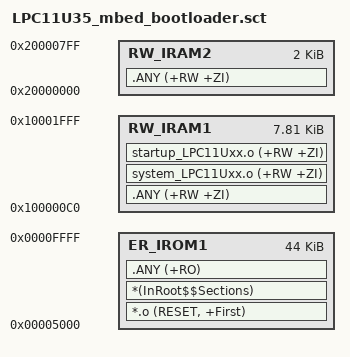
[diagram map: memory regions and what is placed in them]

LR_IROM1 0x00005000 0xb000  {    ; load region size_region (64k)

  ER_IROM1 0x00005000 0xb000  {  ; load address = execution address
   *.o (RESET, +First)
   *(InRoot$$Sections)
   .ANY (+RO)
  }
  
  RW_IRAM1 0x100000c0 0x1f40  {
   .ANY (+RW +ZI)
   system_LPC11Uxx.o (+RW +ZI)
   startup_LPC11Uxx.o (+RW +ZI)
  }
  
  RW_IRAM2 0x20000000 0x800  {
   .ANY (+RW +ZI)
  } 
  
}

